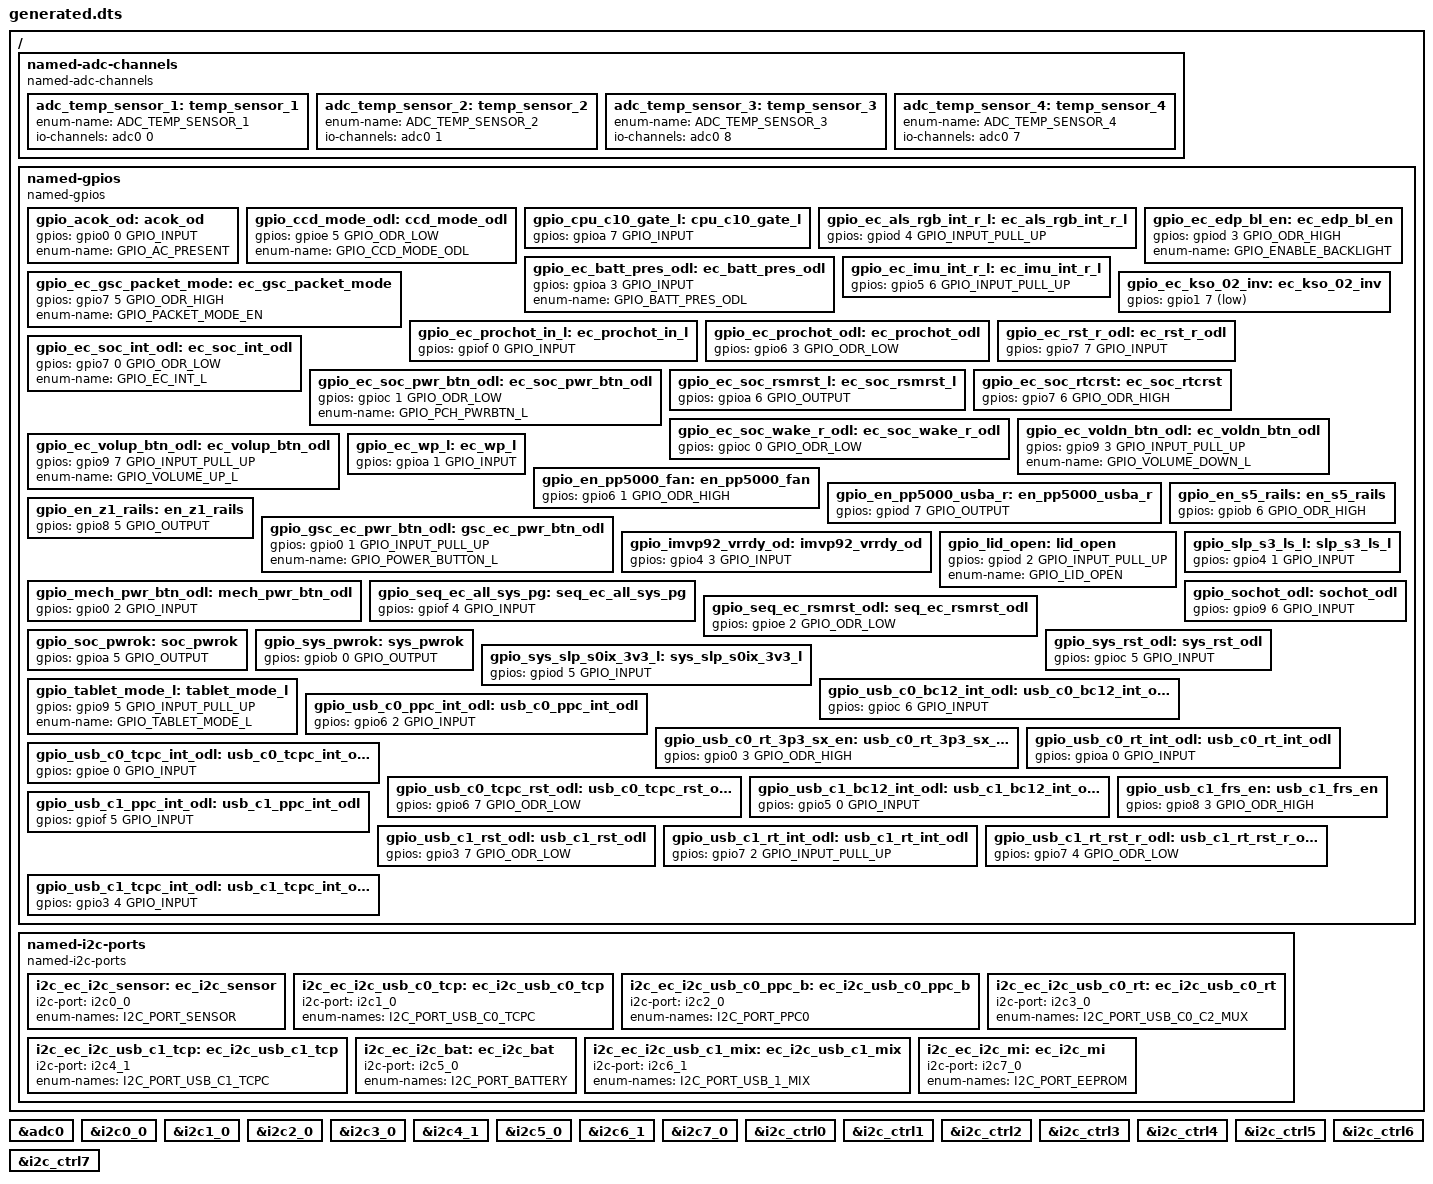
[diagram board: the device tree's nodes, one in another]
/* Copyright 2022 The Chromium OS Authors. All rights reserved.
 * Use of this source code is governed by a BSD-style license that can be
 * found in the LICENSE file.
 *
 * This file is auto-generated - do not edit!
 */

/ {

	named-adc-channels {
		compatible = "named-adc-channels";

		adc_temp_sensor_1: temp_sensor_1 {
			enum-name = "ADC_TEMP_SENSOR_1";
			io-channels = <&adc0 0>;
		};
		adc_temp_sensor_2: temp_sensor_2 {
			enum-name = "ADC_TEMP_SENSOR_2";
			io-channels = <&adc0 1>;
		};
		adc_temp_sensor_3: temp_sensor_3 {
			enum-name = "ADC_TEMP_SENSOR_3";
			io-channels = <&adc0 8>;
		};
		adc_temp_sensor_4: temp_sensor_4 {
			enum-name = "ADC_TEMP_SENSOR_4";
			io-channels = <&adc0 7>;
		};
	};

	named-gpios {
		compatible = "named-gpios";

		gpio_acok_od: acok_od {
			gpios = <&gpio0 0 GPIO_INPUT>;
			enum-name = "GPIO_AC_PRESENT";
		};
		gpio_ccd_mode_odl: ccd_mode_odl {
			gpios = <&gpioe 5 GPIO_ODR_LOW>;
			enum-name = "GPIO_CCD_MODE_ODL";
		};
		gpio_cpu_c10_gate_l: cpu_c10_gate_l {
			gpios = <&gpioa 7 GPIO_INPUT>;
		};
		gpio_ec_als_rgb_int_r_l: ec_als_rgb_int_r_l {
			gpios = <&gpiod 4 GPIO_INPUT_PULL_UP>;
		};
		gpio_ec_batt_pres_odl: ec_batt_pres_odl {
			gpios = <&gpioa 3 GPIO_INPUT>;
			enum-name = "GPIO_BATT_PRES_ODL";
		};
		gpio_ec_edp_bl_en: ec_edp_bl_en {
			gpios = <&gpiod 3 GPIO_ODR_HIGH>;
			enum-name = "GPIO_ENABLE_BACKLIGHT";
		};
		gpio_ec_gsc_packet_mode: ec_gsc_packet_mode {
			gpios = <&gpio7 5 GPIO_ODR_HIGH>;
			enum-name = "GPIO_PACKET_MODE_EN";
		};
		gpio_ec_imu_int_r_l: ec_imu_int_r_l {
			gpios = <&gpio5 6 GPIO_INPUT_PULL_UP>;
		};
		gpio_ec_kso_02_inv: ec_kso_02_inv {
			gpios = <&gpio1 7 (GPIO_OUTPUT | GPIO_ACTIVE_LOW)>;
		};
		gpio_ec_prochot_in_l: ec_prochot_in_l {
			gpios = <&gpiof 0 GPIO_INPUT>;
		};
		gpio_ec_prochot_odl: ec_prochot_odl {
			gpios = <&gpio6 3 GPIO_ODR_LOW>;
		};
		gpio_ec_rst_r_odl: ec_rst_r_odl {
			gpios = <&gpio7 7 GPIO_INPUT>;
		};
		gpio_ec_soc_int_odl: ec_soc_int_odl {
			gpios = <&gpio7 0 GPIO_ODR_LOW>;
			enum-name = "GPIO_EC_INT_L";
		};
		gpio_ec_soc_pwr_btn_odl: ec_soc_pwr_btn_odl {
			gpios = <&gpioc 1 GPIO_ODR_LOW>;
			enum-name = "GPIO_PCH_PWRBTN_L";
		};
		gpio_ec_soc_rsmrst_l: ec_soc_rsmrst_l {
			gpios = <&gpioa 6 GPIO_OUTPUT>;
		};
		gpio_ec_soc_rtcrst: ec_soc_rtcrst {
			gpios = <&gpio7 6 GPIO_ODR_HIGH>;
		};
		gpio_ec_soc_wake_r_odl: ec_soc_wake_r_odl {
			gpios = <&gpioc 0 GPIO_ODR_LOW>;
		};
		gpio_ec_voldn_btn_odl: ec_voldn_btn_odl {
			gpios = <&gpio9 3 GPIO_INPUT_PULL_UP>;
			enum-name = "GPIO_VOLUME_DOWN_L";
		};
		gpio_ec_volup_btn_odl: ec_volup_btn_odl {
			gpios = <&gpio9 7 GPIO_INPUT_PULL_UP>;
			enum-name = "GPIO_VOLUME_UP_L";
		};
		gpio_ec_wp_l: ec_wp_l {
			gpios = <&gpioa 1 GPIO_INPUT>;
		};
		gpio_en_pp5000_fan: en_pp5000_fan {
			gpios = <&gpio6 1 GPIO_ODR_HIGH>;
		};
		gpio_en_pp5000_usba_r: en_pp5000_usba_r {
			gpios = <&gpiod 7 GPIO_OUTPUT>;
		};
		gpio_en_s5_rails: en_s5_rails {
			gpios = <&gpiob 6 GPIO_ODR_HIGH>;
		};
		gpio_en_z1_rails: en_z1_rails {
			gpios = <&gpio8 5 GPIO_OUTPUT>;
		};
		gpio_gsc_ec_pwr_btn_odl: gsc_ec_pwr_btn_odl {
			gpios = <&gpio0 1 GPIO_INPUT_PULL_UP>;
			enum-name = "GPIO_POWER_BUTTON_L";
		};
		gpio_imvp92_vrrdy_od: imvp92_vrrdy_od {
			gpios = <&gpio4 3 GPIO_INPUT>;
		};
		gpio_lid_open: lid_open {
			gpios = <&gpiod 2 GPIO_INPUT_PULL_UP>;
			enum-name = "GPIO_LID_OPEN";
		};
		gpio_mech_pwr_btn_odl: mech_pwr_btn_odl {
			gpios = <&gpio0 2 GPIO_INPUT>;
		};
		gpio_seq_ec_all_sys_pg: seq_ec_all_sys_pg {
			gpios = <&gpiof 4 GPIO_INPUT>;
		};
		gpio_seq_ec_rsmrst_odl: seq_ec_rsmrst_odl {
			gpios = <&gpioe 2 GPIO_ODR_LOW>;
		};
		gpio_slp_s3_ls_l: slp_s3_ls_l {
			gpios = <&gpio4 1 GPIO_INPUT>;
		};
		gpio_sochot_odl: sochot_odl {
			gpios = <&gpio9 6 GPIO_INPUT>;
		};
		gpio_soc_pwrok: soc_pwrok {
			gpios = <&gpioa 5 GPIO_OUTPUT>;
		};
		gpio_sys_pwrok: sys_pwrok {
			gpios = <&gpiob 0 GPIO_OUTPUT>;
		};
		gpio_sys_rst_odl: sys_rst_odl {
			gpios = <&gpioc 5 GPIO_INPUT>;
		};
		gpio_sys_slp_s0ix_3v3_l: sys_slp_s0ix_3v3_l {
			gpios = <&gpiod 5 GPIO_INPUT>;
		};
		gpio_tablet_mode_l: tablet_mode_l {
			gpios = <&gpio9 5 GPIO_INPUT_PULL_UP>;
			enum-name = "GPIO_TABLET_MODE_L";
		};
		gpio_usb_c0_bc12_int_odl: usb_c0_bc12_int_odl {
			gpios = <&gpioc 6 GPIO_INPUT>;
		};
		gpio_usb_c0_ppc_int_odl: usb_c0_ppc_int_odl {
			gpios = <&gpio6 2 GPIO_INPUT>;
		};
		gpio_usb_c0_rt_3p3_sx_en: usb_c0_rt_3p3_sx_en {
			gpios = <&gpio0 3 GPIO_ODR_HIGH>;
		};
		gpio_usb_c0_rt_int_odl: usb_c0_rt_int_odl {
			gpios = <&gpioa 0 GPIO_INPUT>;
		};
		gpio_usb_c0_tcpc_int_odl: usb_c0_tcpc_int_odl {
			gpios = <&gpioe 0 GPIO_INPUT>;
		};
		gpio_usb_c0_tcpc_rst_odl: usb_c0_tcpc_rst_odl {
			gpios = <&gpio6 7 GPIO_ODR_LOW>;
		};
		gpio_usb_c1_bc12_int_odl: usb_c1_bc12_int_odl {
			gpios = <&gpio5 0 GPIO_INPUT>;
		};
		gpio_usb_c1_frs_en: usb_c1_frs_en {
			gpios = <&gpio8 3 GPIO_ODR_HIGH>;
		};
		gpio_usb_c1_ppc_int_odl: usb_c1_ppc_int_odl {
			gpios = <&gpiof 5 GPIO_INPUT>;
		};
		gpio_usb_c1_rst_odl: usb_c1_rst_odl {
			gpios = <&gpio3 7 GPIO_ODR_LOW>;
		};
		gpio_usb_c1_rt_int_odl: usb_c1_rt_int_odl {
			gpios = <&gpio7 2 GPIO_INPUT_PULL_UP>;
		};
		gpio_usb_c1_rt_rst_r_odl: usb_c1_rt_rst_r_odl {
			gpios = <&gpio7 4 GPIO_ODR_LOW>;
		};
		gpio_usb_c1_tcpc_int_odl: usb_c1_tcpc_int_odl {
			gpios = <&gpio3 4 GPIO_INPUT>;
		};
	};

	named-i2c-ports {
		compatible = "named-i2c-ports";

		i2c_ec_i2c_sensor: ec_i2c_sensor {
			i2c-port = <&i2c0_0>;
			enum-names = "I2C_PORT_SENSOR";
		};
		i2c_ec_i2c_usb_c0_tcp: ec_i2c_usb_c0_tcp {
			i2c-port = <&i2c1_0>;
			enum-names = "I2C_PORT_USB_C0_TCPC";
		};
		i2c_ec_i2c_usb_c0_ppc_b: ec_i2c_usb_c0_ppc_b {
			i2c-port = <&i2c2_0>;
			enum-names = "I2C_PORT_PPC0";
		};
		i2c_ec_i2c_usb_c0_rt: ec_i2c_usb_c0_rt {
			i2c-port = <&i2c3_0>;
			enum-names = "I2C_PORT_USB_C0_C2_MUX";
		};
		i2c_ec_i2c_usb_c1_tcp: ec_i2c_usb_c1_tcp {
			i2c-port = <&i2c4_1>;
			enum-names = "I2C_PORT_USB_C1_TCPC";
		};
		i2c_ec_i2c_bat: ec_i2c_bat {
			i2c-port = <&i2c5_0>;
			enum-names = "I2C_PORT_BATTERY";
		};
		i2c_ec_i2c_usb_c1_mix: ec_i2c_usb_c1_mix {
			i2c-port = <&i2c6_1>;
			enum-names = "I2C_PORT_USB_1_MIX";
		};
		i2c_ec_i2c_mi: ec_i2c_mi {
			i2c-port = <&i2c7_0>;
			enum-names = "I2C_PORT_EEPROM";
		};
	};
};

&adc0 {
	status = "okay";
};

&i2c0_0 {
	status = "okay";
};

&i2c1_0 {
	status = "okay";
};

&i2c2_0 {
	status = "okay";
};

&i2c3_0 {
	status = "okay";
};

&i2c4_1 {
	status = "okay";
};

&i2c5_0 {
	status = "okay";
};

&i2c6_1 {
	status = "okay";
};

&i2c7_0 {
	status = "okay";
};

&i2c_ctrl0 {
	status = "okay";
};

&i2c_ctrl1 {
	status = "okay";
};

&i2c_ctrl2 {
	status = "okay";
};

&i2c_ctrl3 {
	status = "okay";
};

&i2c_ctrl4 {
	status = "okay";
};

&i2c_ctrl5 {
	status = "okay";
};

&i2c_ctrl6 {
	status = "okay";
};

&i2c_ctrl7 {
	status = "okay";
};
